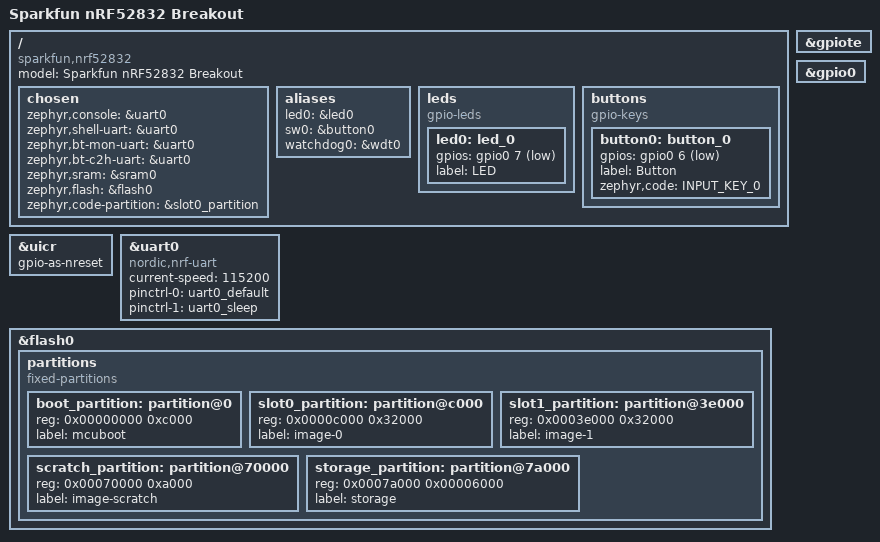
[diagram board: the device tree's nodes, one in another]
/*
 * Copyright (c) 2017 Shawn Nock <shawn@monadnock.ca>
 * Copyright (c) 2017 Linaro Limited
 *
 * SPDX-License-Identifier: Apache-2.0
 */

/dts-v1/;
#include <nordic/nrf52832_qfaa.dtsi>
#include "nrf52_sparkfun-pinctrl.dtsi"
#include <zephyr/dt-bindings/input/input-event-codes.h>

/ {
	compatible = "sparkfun,nrf52832";
	model = "Sparkfun nRF52832 Breakout";

	chosen {
		zephyr,console = &uart0;
		zephyr,shell-uart = &uart0;
		zephyr,bt-mon-uart = &uart0;
		zephyr,bt-c2h-uart = &uart0;
		zephyr,sram = &sram0;
		zephyr,flash = &flash0;
		zephyr,code-partition = &slot0_partition;
	};

	/* These aliases are provided for compatibility with samples */
	aliases {
		led0 = &led0;
		sw0 = &button0;
		watchdog0 = &wdt0;
	};

	leds {
		compatible = "gpio-leds";

		led0: led_0 {
			gpios = <&gpio0 7 GPIO_ACTIVE_LOW>;
			label = "LED";
		};
	};

	buttons {
		compatible = "gpio-keys";

		button0: button_0 {
			/* gpio flags need validation */
			gpios = <&gpio0 6 (GPIO_PULL_UP | GPIO_ACTIVE_LOW)>;
			label = "Button";
			zephyr,code = <INPUT_KEY_0>;
		};
	};
};

&uicr {
	gpio-as-nreset;
};

&gpiote {
	status = "okay";
};

&gpio0 {
	status = "okay";
};

&uart0 {
	compatible = "nordic,nrf-uart";
	current-speed = <115200>;
	pinctrl-0 = <&uart0_default>;
	pinctrl-1 = <&uart0_sleep>;
	pinctrl-names = "default", "sleep";
	status = "okay";
};

&flash0 {
	partitions {
		compatible = "fixed-partitions";
		#address-cells = <1>;
		#size-cells = <1>;

		boot_partition: partition@0 {
			reg = <0x00000000 0xc000>;
			label = "mcuboot";
		};

		slot0_partition: partition@c000 {
			reg = <0x0000c000 0x32000>;
			label = "image-0";
		};

		slot1_partition: partition@3e000 {
			reg = <0x0003e000 0x32000>;
			label = "image-1";
		};

		scratch_partition: partition@70000 {
			reg = <0x00070000 0xa000>;
			label = "image-scratch";
		};

		storage_partition: partition@7a000 {
			reg = <0x0007a000 0x00006000>;
			label = "storage";
		};
	};
};
